AUTOSAR XML (schema 3.2.1)
package /TERootContainer
  composition type Power_Window
    8 x require port:
      PW_cls_unlock: required-interface=cls_unlock
      PW_cls_lock: required-interface=cls_lock
      PW_fp_off: required-interface=fp_off
      PW_pw_pos_dn: required-interface=pw_pos_dn
      PW_fp_on: required-interface=fp_on
      PW_pw_pos_up: required-interface=pw_pos_up
      PW_pw_but_up: required-interface=pw_but_up
      PW_pw_but_dn: required-interface=pw_but_dn
    5 x provide port:
      PW_pw_auto_mv_stop: provided-interface=pw_auto_mv_stop
      PW_pw_auto_mv_up: provided-interface=pw_auto_mv_up
      PW_pw_auto_mv_dn: provided-interface=pw_auto_mv_dn
      PW_pw_mv_dn: provided-interface=pw_mv_dn
      PW_pw_mv_up: provided-interface=pw_mv_up
    component ManPW: type=ManPW
    component AutoPW: type=AutoPW_1
    delegate AutoPW.pw_auto_mv_stop <-> outer port PW_pw_auto_mv_stop
    delegate AutoPW.pw_auto_mv_up <-> outer port PW_pw_auto_mv_up
    delegate AutoPW.pw_auto_mv_dn <-> outer port PW_pw_auto_mv_dn
    delegate ManPW.pw_mv_dn <-> outer port PW_pw_mv_dn
    delegate ManPW.pw_mv_up <-> outer port PW_pw_mv_up
    delegate AutoPW.AUtoPW_cls_unlock <-> outer port PW_cls_unlock
    delegate AutoPW.AutoPW_cls_lock <-> outer port PW_cls_lock
    delegate AutoPW.AutoPW_fp_off <-> outer port PW_fp_off
    delegate AutoPW.AutoPW_fp_on <-> outer port PW_fp_on
    delegate AutoPW.AutoPW_pw_but_dn <-> outer port PW_pw_pos_dn
    delegate AutoPW.AutpPW_pw_but_up <-> outer port PW_pw_pos_up
    delegate AutoPW.AutoPW_pw_pos_up <-> outer port PW_pw_but_up
    delegate AutoPW.AutoPW_pw_pos_dn <-> outer port PW_pw_but_dn
    delegate ManPW.ManPW_cls_unlock <-> outer port PW_cls_unlock
    delegate ManPW.ManPW_cls_lock <-> outer port PW_cls_lock
    delegate ManPW.ManPW_fp_off <-> outer port PW_fp_off
    delegate ManPW.ManPW_fp_on <-> outer port PW_fp_on
    delegate ManPW.ManPW_pw_but_dn <-> outer port PW_pw_pos_dn
    delegate ManPW.ManPW_pw_but_up <-> outer port PW_pw_pos_up
    delegate ManPW.ManPW_pw_pos_up <-> outer port PW_pw_but_up
    delegate ManPW.ManPW_pw_pos_dn <-> outer port PW_pw_but_dn
  composition type ManPW
    8 x require port:
      ManPW_cls_unlock: required-interface=cls_unlock
      ManPW_cls_lock: required-interface=cls_lock
      ManPW_fp_off: required-interface=fp_off
      ManPW_fp_on: required-interface=fp_on
      ManPW_pw_pos_dn: required-interface=pw_but_dn
      ManPW_pw_pos_up: required-interface=pw_but_up
      ManPW_pw_but_up: required-interface=pw_pos_up
      ManPW_pw_but_dn: required-interface=pw_pos_dn
    provide port pw_mv_dn: provided-interface=pw_mv_dn
    provide port pw_mv_up: provided-interface=pw_mv_up
  composition type System_Software_Architecture  # System Software Architecture
    51 x component:
      Power_Window: type=Power_Window
      LED_AlarmSystemInteriorMonit: type=LED_AlarmSystemInteriorMonit_1  # LED_AlarmSystemInteriorMonitoring
      LED_AlarmSystemAlarm: type=LED_AlarmSystemAlarm_1
      LED_AlarmSystemAlarmDetected: type=LED_AlarmSystemAlarmDetected_1
      LED_AlaramSystemActive: type=LED_AlaramSystemActive_1
      LED_CentralLockingSystem: type=LED_CentralLockingSystem_1
      LED_FingerProtection: type=LED_FingerProtection_1
      LED_ExteriorMirrorHeating: type=LED_ExteriorMirrorHeating_1
      LED_ExteriorMirrorBottom: type=LED_ExteriorMirrorBottom_1
      LED_ExteriorMirrorRight: type=LED_ExteriorMirrorRight_1
      LED_ExteriorMirrorLeft: type=LED_ExteriorMirrorLeft_1
      LED_ExteriorMirrorTop: type=LED_ExteriorMirrorTop_1
      LED_AutomaticPowerWindow: type=LED_AutomaticPowerWindow_1
      LED_ManualPowerWindow: type=LED_ManualPowerWindow_1
      HumanMachineInterface: type=HumanMachineInterface_1
      CentralLockingSystem: type=CentralLockingSystem_1
      RemoteControlKeyController: type=RemoteControlKeyController_1
      AlarmSystem: type=AlarmSystem_1
      FingerProtection: type=FingerProtection_1
      ExteriorMirror: type=ExteriorMirror_1
      PW_Remote_Control: type=PW_Remote_Control
      Remote_Cotroll_Key: type=Remote_Cotroll_Key
      PW_Button_DN: type=PW_Button_DN
      PW_Button_UP: type=PW_Button_UP
      Alarm_System_Control: type=Alarm_System_Control
      EM_Button: type=EM_Button
      Alarm_Sensor: type=Alarm_Sensor
      LED_ASIM: type=LED_ASIM
      LED_ASAC: type=LED_ASAC
      LED_ASA: type=LED_ASA
      LED_ASAD: type=LED_ASAD
      LED_PW_CLS_UP: type=LED_PW_CLS_UP
      LED_PW_down: type=LED_PW_down
      LED_PW_UP: type=LED_PW_UP
      LED_Heating: type=LED_Heating
      LED_EM_Left: type=LED_EM_Left
      LED_EM_Right: type=LED_EM_Right
      LED_EM_Top: type=LED_EM_Top
      LED_EM_Bottom: type=LED_EM_Bottom
      EM_Motor: type=EM_Motor
      LED_FP: type=LED_FP
      Heating_timer: type=Heating_timer
      Thermometer: type=Thermometer
      EM_Pos_Sensor: type=EM_Pos_Sensor
      Finger_Sensor_SWA: type=Finger_Sensor_SWA
      PW_pos_Sensor: type=PW_pos_Sensor
      Car_locking_system: type=Car_locking_system
      door_sensor: type=door_sensor
      driving_sensor: type=driving_sensor
      Key_Pos_Sensor: type=Key_Pos_Sensor
      CLS_LED: type=CLS_LED
    connect .PW_pw_mv_dn -> LED_ManualPowerWindow.pw_mv_dn
    connect .PW_pw_mv_up -> LED_ManualPowerWindow.pw_mv_up
    connect .PW_pw_auto_mv_dn -> LED_AutomaticPowerWindow.pw_auto_mv_dn  # PW_to_LED_AutoPW_pw_auto_mv_dn
    connect .PW_pw_auto_mv_up -> LED_AutomaticPowerWindow.pw_auto_mv_up  # PW_to_LED_AutpPW_pw_auto_mv_up
    connect .PW_pw_auto_mv_stop -> LED_AutomaticPowerWindow.pw_auto_mv_stop  # PW_to_LED_AutpPW_pw_auto_mv_stop
    connect PW_pos_Sensor.pw_pos_dn -> .PW_pw_pos_dn
    connect PW_pos_Sensor.pw_pos_up -> .PW_pw_pos_up
    connect HumanMachineInterface.pw_but_up -> .PW_pw_but_up
    connect FingerProtection.fp_off -> .PW_fp_off
    connect FingerProtection.fp_on -> .PW_fp_on
    connect CentralLockingSystem.cls_unlock -> .PW_cls_unlock
    connect CentralLockingSystem.cls_lock -> .PW_cls_lock
    connect RemoteControlKeyController.pw_but_dn -> .PW_pw_but_dn
    connect RemoteControlKeyController.pw_but_up -> .PW_pw_but_up
    connect HumanMachineInterface.pw_but_dn -> .PW_pw_but_dn
    connect Key_Pos_Sensor.key_pos_unlock -> AlarmSystem.key_pos_unlock  # Key_Pos_Sensor_to_AS_key_pos_unlock
    connect Key_Pos_Sensor.key_pos_lock -> AlarmSystem.key_pos_lock  # Key_pos_Sensor_to_AS_key_pos_lock
    connect RemoteControlKeyController.rck_unlock -> AlarmSystem.rck_unlock
    connect RemoteControlKeyController.rck_lock -> AlarmSystem.rck_lock
    connect RemoteControlKeyController.rck_unlock -> CentralLockingSystem.rck_unlock
    connect RemoteControlKeyController.rck_lock -> CentralLockingSystem.rck_lock
    connect door_sensor.door_open -> CentralLockingSystem.door_open
    connect door_sensor.door_open -> RemoteControlKeyController.door_open  # Door_Sensor_to_RCKC_door_open
    connect LED_AlarmSystemInteriorMonit.led_as_im_alarm_off -> LED_ASIM.led_off
    connect LED_AlarmSystemInteriorMonit.led_as_im_alarm_on -> LED_ASIM.led_on
    connect LED_AlaramSystemActive.led_as_active_off -> LED_ASAC.led_off
    connect LED_AlaramSystemActive.led_as_active_on -> LED_ASAC.led_on
    connect LED_AlarmSystemAlarm.led_as_alarm_off -> LED_ASA.led_off
    connect LED_AlarmSystemAlarm.led_as_alarm_on -> LED_ASA.led_on
    connect LED_AlarmSystemAlarmDetected.led_as_alarm_detected_off -> LED_ASAD.led_off
    connect LED_AlarmSystemAlarmDetected.led_as_alarm_detected_on -> LED_ASAD.led_on
    connect LED_AutomaticPowerWindow.led_pw_dn_off -> LED_PW_down.led_off  # LED_AUTOPW_to_LED_PW_down_off
    connect LED_AutomaticPowerWindow.led_pw_dn_on -> LED_PW_down.led_on
    connect LED_ManualPowerWindow.led_pw_dn_on -> LED_PW_down.led_on
    connect LED_AutomaticPowerWindow.led_pw_cls_up_on -> LED_PW_CLS_UP.led_on  # LED_AUTOPW_to_LED_PW_CLS_UP_on
    connect LED_AutomaticPowerWindow.led_pw_cls_up_off -> LED_PW_CLS_UP.led_off  # LED_AUTOPW_to_LED_PW_CLS_UP_off
    connect LED_ManualPowerWindow.led_pw_dn_off -> LED_PW_down.led_off
    connect LED_ManualPowerWindow.led_pw_up_off -> LED_PW_UP.led_off
    connect LED_ManualPowerWindow.led_pw_up_on -> LED_PW_UP.led_on
    connect LED_AutomaticPowerWindow.led_pw_up_off -> LED_PW_UP.led_off
    connect LED_AutomaticPowerWindow.led_pw_up_on -> LED_PW_UP.led_on
    connect LED_ExteriorMirrorHeating.led_em_heating_off -> LED_Heating.led_off  # LED_EM_Heating_to_LED_Heating_off
    connect LED_ExteriorMirrorHeating.led_em_heating_on -> LED_Heating.led_on  # LED_EM_Heating_to_LED_Heating_on
    connect LED_ExteriorMirrorLeft.led_em_left_off -> LED_EM_Left.led_off  # LED_EM_Left_to_LED_EM_Left_off
    connect LED_ExteriorMirrorLeft.led_em_left_on -> LED_EM_Left.led_on  # LED_EM_Left_to_LED_EM_Left_on
    connect LED_ExteriorMirrorRight.led_em_right_off -> LED_EM_Right.led_off  # LED_EM_Right_to_LED_EM_Right_off
    connect LED_ExteriorMirrorRight.led_em_right_on -> LED_EM_Right.led_on  # LED_EM_Right_to_LED_EM_Right_on
    connect LED_ExteriorMirrorTop.led_em_top_off -> LED_EM_Top.led_off
    connect LED_ExteriorMirrorTop.led_em_top_on -> LED_EM_Top.led_on
    connect LED_ExteriorMirrorBottom.led_em_bottom_off -> LED_EM_Bottom.led_off  # LED_EM_Bottom_to_LED_EM_Bottom_off
    connect LED_ExteriorMirrorBottom.led_em_bottom_on -> LED_EM_Bottom.led_on  # LED_EM_Bottom_to_LED_EM_Bottom_on
    connect LED_FingerProtection.led_fp_off -> LED_FP.led_fp_off  # LED_Fingerprotection_to_LED_FP_off
    connect LED_FingerProtection.led_fp_on -> LED_FP.led_fp_on  # LED_Fingerprotection_to_LED_FP_on
    connect Finger_Sensor_SWA.finger_detected -> FingerProtection.finger_detected  # Finger_Snesor_to_FP_finger_detected
    connect ExteriorMirror.em_mv_down -> EM_Motor.em_mv_down
    connect ExteriorMirror.em_mv_up -> EM_Motor.em_mv_up
    connect ExteriorMirror.em_mv_right -> EM_Motor.em_mv_right
    connect ExteriorMirror.em_mv_left -> EM_Motor.em_mv_left
    connect Heating_timer.heating_time_elapsed -> ExteriorMirror.time_heating_elapsed  # Heating_Timer_to_EM_heating_time_elapsed
    connect Thermometer.em_too_cold -> ExteriorMirror.em_too_cold
    connect EM_Pos_Sensor.em_pos_top -> ExteriorMirror.em_pos_top
    connect EM_Pos_Sensor.em_pos_bottom -> ExteriorMirror.em_pos_bottom  # EM_Pos_Sensor_to_EM_pos_bottom
    connect EM_Pos_Sensor.em_pos_right -> ExteriorMirror.em_pos_right  # EM_Pos_Sensor_to_EM_pos_right
    connect EM_Pos_Sensor.em_pos_left -> ExteriorMirror.em_pos_left
    connect Alarm_Sensor.im_alarm_detected -> AlarmSystem.im_alarm_detected  # Alarm_Sensor_to_Alarm_System_im_alarm_detected
    connect Alarm_Sensor.alarm_detected -> AlarmSystem.as_alarm_detected  # Alarm_Sensor_to_Alarm_System_alarm_detected
    connect Alarm_Sensor.alarm_time_elapsed -> AlarmSystem.time_alarm_elapsed  # Alarm_Sensor_to_Alarm_System_time_alarm_elapsed
    connect Key_Pos_Sensor.key_pos_unlock -> CentralLockingSystem.key_pos_unlock
    connect Key_Pos_Sensor.key_pos_lock -> CentralLockingSystem.key_pos_lock
    connect driving_sensor.car_drives -> CentralLockingSystem.car_drives  # Drinving_Sensor_to_CLS_car_drives
    connect PW_Remote_Control.pw_but_down -> RemoteControlKeyController.pw_rm_dn
    connect PW_Remote_Control.pw_but_up -> RemoteControlKeyController.pw_rm_up
    connect Remote_Cotroll_Key.rck_timer -> RemoteControlKeyController.time_rck_sf_elapsed
    connect Remote_Cotroll_Key.rck_but_unlock -> RemoteControlKeyController.rck_but_unlock
    connect Remote_Cotroll_Key.rck_but_lock -> RemoteControlKeyController.rck_but_lock
    connect PW_Button_DN.pw_but_released -> HumanMachineInterface.release_pw_but_dn
    connect PW_Button_DN.pw_but_pressed -> HumanMachineInterface.pw_but_mv_dn
    connect PW_Button_UP.pw_but_released -> HumanMachineInterface.release_pw_but_up
    connect PW_Button_UP.pw_but_pressed -> HumanMachineInterface.pw_but_mv_up
    connect Alarm_System_Control.confirm_alarm -> HumanMachineInterface.confirm_alarm
    connect Alarm_System_Control.deactivate_as -> HumanMachineInterface.deactivate_as
    connect Alarm_System_Control.activate_as -> HumanMachineInterface.activate_as
    connect EM_Button.em_but_mv_dn -> HumanMachineInterface.em_but_mv_dn
    connect EM_Button.em_but_mv_up -> HumanMachineInterface.em_but_mv_up
    connect EM_Button.em_but_mv_right -> HumanMachineInterface.em_but_mv_right  # EM_Button_to_HMI_but_mv_right
    connect EM_Button.em_but_mv_left -> HumanMachineInterface.em_but_mv_left
    connect CentralLockingSystem.car_unlock -> Car_locking_system.car_unlock
    connect CentralLockingSystem.car_lock -> Car_locking_system.car_lock
    connect LED_CentralLockingSystem.led_cls_off -> CLS_LED.led_cls_off
    connect LED_CentralLockingSystem.led_cls_on -> CLS_LED.led_cls_on
    connect ExteriorMirror.heating_on -> LED_ExteriorMirrorHeating.heating_on
    connect ExteriorMirror.heating_off -> LED_ExteriorMirrorHeating.heating_off
    connect ExteriorMirror.em_pos_hor_left -> LED_ExteriorMirrorLeft.em_pos_hor_left  # EM_to_LED_EML_em_pos_hor_left
    connect ExteriorMirror.em_pos_hor_pend -> LED_ExteriorMirrorLeft.em_pos_hor_pend  # EM_to_LED_EML_em_pos_hor_pend
    connect ExteriorMirror.em_pos_hor_pend -> LED_ExteriorMirrorRight.em_pos_hor_pend  # EM_to_LED_EMR_em_pos_hor_pend
    connect ExteriorMirror.em_pos_hor_right -> LED_ExteriorMirrorRight.em_pos_hor_right  # EM_to_LED_EMR_em_pos_hor_right
    connect ExteriorMirror.em_pos_vert_top -> LED_ExteriorMirrorTop.em_pos_vert_top  # EM_to_LED_EMT_em_pos_vert_top
    connect ExteriorMirror.em_pos_vert_pend -> LED_ExteriorMirrorTop.em_pos_vert_pend  # EM_to_LED_EMT_em_pos_vert_pend
    connect ExteriorMirror.em_pos_vert_pend -> LED_ExteriorMirrorBottom.em_pos_vert_pend  # EM_to_LED_EMB_em_pos_vert_pend
    connect ExteriorMirror.em_pos_vert_bottom -> LED_ExteriorMirrorBottom.em_pos_vert_bottom  # EM_to_LED_EMB_em_pos_vert_bottom
    connect HumanMachineInterface.release_pw_but -> LED_ManualPowerWindow.release_pw_but  # HMI_to_LED_ManPW_release_pw_but
    connect AlarmSystem.as_im_alarm_off -> LED_AlarmSystemInteriorMonit.as_im_alarm_off  # AS_to_LED_ASIM_as_im_alarm_off
    connect AlarmSystem.as_im_alarm_on -> LED_AlarmSystemInteriorMonit.as_im_alarm_on  # AS_to_LED_ASIM_as_im_alarm_on
    connect AlarmSystem.as_active_off -> LED_AlaramSystemActive.as_active_off
    connect AlarmSystem.as_active_on -> LED_AlaramSystemActive.as_active_on
    connect CentralLockingSystem.cls_lock -> LED_AutomaticPowerWindow.cls_lock
    connect CentralLockingSystem.cls_unlock -> LED_AutomaticPowerWindow.cls_unlock
    connect AlarmSystem.as_alarm_off -> LED_AlarmSystemAlarm.as_alarm_off
    connect AlarmSystem.as_alarm_on -> LED_AlarmSystemAlarm.as_alarm_on
    connect AlarmSystem.as_alarm_was_detected -> LED_AlarmSystemAlarmDetected.as_alarm_was_detected  # AS_to_LED_ASAD_as_alarm_was_detected
    connect HumanMachineInterface.as_alarm_was_confirmed -> LED_AlarmSystemAlarmDetected.as_alarm_was_confirmed  # HMI_LED_ASAD_alram_was_confirmed
    connect FingerProtection.fp_off -> LED_FingerProtection.fp_off
    connect FingerProtection.fp_on -> LED_FingerProtection.fp_on
    connect HumanMachineInterface.as_activated -> AlarmSystem.as_activated
    connect HumanMachineInterface.as_deactivated -> AlarmSystem.as_deactivated
    connect CentralLockingSystem.cls_lock -> LED_CentralLockingSystem.cls_lock
    connect CentralLockingSystem.cls_unlock -> LED_CentralLockingSystem.cls_unlock
    connect HumanMachineInterface.pw_but_dn -> FingerProtection.pw_but_dn
    connect HumanMachineInterface.em_but_left -> ExteriorMirror.em_but_left
    connect HumanMachineInterface.em_but_up -> ExteriorMirror.em_but_up
    connect HumanMachineInterface.em_but_dn -> ExteriorMirror.em_but_down
    connect HumanMachineInterface.em_but_right -> ExteriorMirror.em_but_right
package /SystemInformation
  system System_System_Software_Architecture:
    fibex-element=[ECU2_HMI, ECU1_Doorsystem, CLS_ECU4, Alarm_System_ECU3, LED_PW_Up, LED_PW_DN, LED_PW_CLS, LED_FP, LED_EMT, LED_EMR, LED_EML, LED_EMB, LED_EM_Heating, LED_CLS, LED_ASIM, LED_ASAL, LED_ASAD, LED_ASAC, EM_Motor, Car_Locking_System, Thermoeter, Remote_Control_Key, RCK_PW_Buttons, PW_Position_Sensor, PW_But_UP, PW_But_DN, Key_Pos_Sensor, Heating_Timer, Finger_Sensor_HW, EM_Pos_Sensor, EM_Button, Driving_Snesor, Door_Sensor, Alarm_System_Control, Alarm_Sensor]
    pnc-vector-length=0
    pnc-vector-offset=0
    mapping Mapping
      sw-impl-mappings:
        20 x swc to impl mapping:
          swcMapping_FingerProtection: component-implementation=Impl_FingerProtection, component=System_Software_Architecture.FingerProtection
          swcMapping_LED_AlarmSystemAl_1: component-implementation=Impl_LED_AlarmSystemAlarmDet, component=System_Software_Architecture.LED_AlarmSystemAlarmDetected
          swcMapping_LED_ExteriorMirro_4: component-implementation=Impl_LED_ExteriorMirrorTop, component=System_Software_Architecture.LED_ExteriorMirrorTop
          swcMapping_AutoPW: component-implementation=Impl_AutoPW, component=System_Software_Architecture.Power_Window.AutoPW
          swcMapping_LED_ManualPowerWi: component-implementation=Impl_LED_ManualPowerWindow, component=System_Software_Architecture.LED_ManualPowerWindow
          swcMapping_LED_ExteriorMirro_2: component-implementation=Impl_LED_ExteriorMirrorRight, component=System_Software_Architecture.LED_ExteriorMirrorRight
          swcMapping_ExteriorMirror: component-implementation=Impl_ExteriorMirror, component=System_Software_Architecture.ExteriorMirror
          swcMapping_LED_ExteriorMirro_3: component-implementation=Impl_LED_ExteriorMirrorLeft, component=System_Software_Architecture.LED_ExteriorMirrorLeft
          swcMapping_LED_AlaramSystemA: component-implementation=Impl_LED_AlaramSystemActive, component=System_Software_Architecture.LED_AlaramSystemActive
          swcMapping_RemoteControlKeyC: component-implementation=Impl_RemoteControlKeyControl, component=System_Software_Architecture.RemoteControlKeyController
          swcMapping_LED_ExteriorMirro_1: component-implementation=Impl_LED_ExteriorMirrorBotto, component=System_Software_Architecture.LED_ExteriorMirrorBottom
          swcMapping_LED_AlarmSystemAl: component-implementation=Impl_LED_AlarmSystemAlarm, component=System_Software_Architecture.LED_AlarmSystemAlarm
          swcMapping_LED_FingerProtect: component-implementation=Impl_LED_FingerProtection, component=System_Software_Architecture.LED_FingerProtection
          swcMapping_LED_AlarmSystemIn: component-implementation=Impl_LED_AlarmSystemInterior, component=System_Software_Architecture.LED_AlarmSystemInteriorMonit
          swcMapping_LED_AutomaticPowe: component-implementation=Impl_LED_AutomaticPowerWindo, component=System_Software_Architecture.LED_AutomaticPowerWindow
          swcMapping_CentralLockingSys: component-implementation=Impl_CentralLockingSystem, component=System_Software_Architecture.CentralLockingSystem
          swcMapping_LED_CentralLockin: component-implementation=Impl_LED_CentralLockingSyste, component=System_Software_Architecture.LED_CentralLockingSystem
          swcMapping_LED_ExteriorMirro: component-implementation=Impl_LED_ExteriorMirrorHeati, component=System_Software_Architecture.LED_ExteriorMirrorHeating
          swcMapping_HumanMachineInter: component-implementation=Impl_HumanMachineInterface, component=System_Software_Architecture.HumanMachineInterface
          swcMapping_AlarmSystem: component-implementation=Impl_AlarmSystem, component=System_Software_Architecture.AlarmSystem
      sw-mappings:
        34 x swc to ecu mapping:
          LED_EMB_FBMapping: component=System_Software_Architecture.LED_EM_Bottom, ecu-instance=LED_EMB
          LED_EMR_FBMapping: component=System_Software_Architecture.LED_EM_Right, ecu-instance=LED_EMR
          LED_EML_FBMapping: component=System_Software_Architecture.LED_EM_Left, ecu-instance=LED_EML
          ECU2_HMI_FBMapping: ecu-instance=ECU2_HMI
            component:
              System_Software_Architecture.LED_ExteriorMirrorBottom
              System_Software_Architecture.LED_ExteriorMirrorRight
              System_Software_Architecture.LED_FingerProtection
              System_Software_Architecture.LED_ExteriorMirrorHeating
              System_Software_Architecture.LED_ExteriorMirrorLeft
              System_Software_Architecture.LED_ManualPowerWindow
              System_Software_Architecture.LED_AutomaticPowerWindow
              System_Software_Architecture.HumanMachineInterface
              System_Software_Architecture.LED_CentralLockingSystem
              System_Software_Architecture.LED_ExteriorMirrorTop
              System_Software_Architecture.LED_AlarmSystemAlarm
              System_Software_Architecture.LED_AlarmSystemInteriorMonit
              System_Software_Architecture.LED_AlaramSystemActive
              System_Software_Architecture.LED_AlarmSystemAlarmDetected
          ECU1_Doorsystem_FBMapping: ecu-instance=ECU1_Doorsystem
            component:
              System_Software_Architecture.ExteriorMirror
              System_Software_Architecture.Power_Window.ManPW
              System_Software_Architecture.FingerProtection
              System_Software_Architecture.Power_Window.AutoPW
          Finger_Sensor_HW_FBMapping: component=System_Software_Architecture.Finger_Sensor_SWA, ecu-instance=Finger_Sensor_HW
          Remote_Control_Key_FBMapping: component=System_Software_Architecture.Remote_Cotroll_Key, ecu-instance=Remote_Control_Key
          Key_Pos_Sensor_FBMapping: component=System_Software_Architecture.Key_Pos_Sensor, ecu-instance=Key_Pos_Sensor
          RCK_PW_Buttons_FBMapping: component=System_Software_Architecture.PW_Remote_Control, ecu-instance=RCK_PW_Buttons
          EM_Motor_FBMapping: component=System_Software_Architecture.EM_Motor, ecu-instance=EM_Motor
          LED_CLS_FBMapping: component=[System_Software_Architecture.CLS_LED, System_Software_Architecture.LED_PW_CLS_UP], ecu-instance=LED_CLS
          CLS_ECU4_FBMapping: ecu-instance=CLS_ECU4
            component:
              System_Software_Architecture.CentralLockingSystem
              System_Software_Architecture.RemoteControlKeyController
          LED_EM_Heating_FBMapping: component=System_Software_Architecture.LED_Heating, ecu-instance=LED_EM_Heating
          PW_Position_Sensor_FBMapping: component=System_Software_Architecture.PW_pos_Sensor, ecu-instance=PW_Position_Sensor
          PW_But_UP_FBMapping: component=System_Software_Architecture.PW_Button_UP, ecu-instance=PW_But_UP
          Car_Locking_System_FBMapping: component=System_Software_Architecture.Car_locking_system, ecu-instance=Car_Locking_System
          LED_ASAL_FBMapping: component=System_Software_Architecture.LED_ASA, ecu-instance=LED_ASAL
          Alarm_System_Control_FBMappi: component=System_Software_Architecture.Alarm_System_Control, ecu-instance=Alarm_System_Control
          EM_Button_FBMapping: component=System_Software_Architecture.EM_Button, ecu-instance=EM_Button
          Alarm_System_ECU3_FBMapping: component=System_Software_Architecture.AlarmSystem, ecu-instance=Alarm_System_ECU3
          LED_EMT_FBMapping: component=System_Software_Architecture.LED_EM_Top, ecu-instance=LED_EMT
          LED_PW_DN_FBMapping: component=System_Software_Architecture.LED_PW_down, ecu-instance=LED_PW_DN
          LED_ASAD_FBMapping: component=System_Software_Architecture.LED_ASAD, ecu-instance=LED_ASAD
          Door_Sensor_FBMapping: component=System_Software_Architecture.door_sensor, ecu-instance=Door_Sensor
          Thermoeter_FBMapping: component=System_Software_Architecture.Thermometer, ecu-instance=Thermoeter
          Alarm_Sensor_FBMapping: component=System_Software_Architecture.Alarm_Sensor, ecu-instance=Alarm_Sensor
          Heating_Timer_FBMapping: component=System_Software_Architecture.Heating_timer, ecu-instance=Heating_Timer
          LED_ASAC_FBMapping: component=System_Software_Architecture.LED_ASAC, ecu-instance=LED_ASAC
          Driving_Snesor_FBMapping: component=System_Software_Architecture.driving_sensor, ecu-instance=Driving_Snesor
          LED_FP_FBMapping: component=System_Software_Architecture.LED_FP, ecu-instance=LED_FP
          PW_But_DN_FBMapping: component=System_Software_Architecture.PW_Button_DN, ecu-instance=PW_But_DN
          LED_ASIM_FBMapping: component=System_Software_Architecture.LED_ASIM, ecu-instance=LED_ASIM
          LED_PW_Up_FBMapping: component=System_Software_Architecture.LED_PW_UP, ecu-instance=LED_PW_Up
          EM_Pos_Sensor_FBMapping: component=System_Software_Architecture.EM_Pos_Sensor, ecu-instance=EM_Pos_Sensor
    software composition System_Software_Architecture: software-composition=System_Software_Architecture
package /Software_Types  # Software Types
package /Software_Types/Interface_Types  # Interface Types
package /Software_Types/Interface_Types/Sender__Receiver_Interfaces  # Sender-/Receiver Interfaces
package /Software_Types/Interface_Types/Sender__Receiver_Interfaces/BCS_Basic/signal_output
  34 x sender receiver interface:
    led_as_im_alarm_off
    led_as_im_alarm_on
    led_as_active_off
    led_as_active_on
    led_as_alarm_off
    led_as_alarm_on
    led_as_alarm_detected_off
    led_as_alarm_detected_on
    led_fp_off
    led_fp_on
    led_cls_off
    led_cls_on
    led_em_heating_off
    led_em_heating_on
    led_em_right_off
    led_em_right_on
    led_em_left_off
    led_em_left_on
    led_em_top_off
    led_em_top_on
    led_em_bottom_off
    led_em_bottom_on
    led_pw_cls_up_off
    led_pw_cls_up_on
    led_pw_dn_off
    led_pw_dn_on
    led_pw_up_off
    led_pw_up_on
    car_unlock
    car_lock
    em_mv_up
    em_mv_right
    em_mv_left
    em_mv_down
package /Software_Types/Interface_Types/Sender__Receiver_Interfaces/BCS_Basic/signal_internal
  36 x sender receiver interface:
    fp_on
    fp_off
    pw_mv_up
    pw_mv_dn
    pw_auto_mv_up
    pw_auto_mv_stop
    pw_auto_mv_dn
    as_alarm_was_confirmed
    release_pw_but
    cls_unlock
    cls_lock
    as_im_alarm_off
    as_im_alarm_on
    as_active_off
    as_active_on
    as_alarm_off
    as_alarm_on
    as_alarm_was_detected
    rck_unlock
    rck_lock
      data rck_lock
    as_deactivated
    as_activated
    heating_off
    heating_on
    em_pos_hor_right
    em_pos_hor_left
    em_pos_vert_top
    em_pos_hor_pend
    em_pos_vert_pend
    em_pos_vert_bottom
    em_but_up
    em_but_left
    em_but_down
    em_but_right
    pw_but_up
    pw_but_dn
package /Software_Types/Interface_Types/Sender__Receiver_Interfaces/BCS_Basic/signal_input
  32 x sender receiver interface:
    finger_detected
    release_pw_but_dn
    release_pw_but_up
    confirm_alarm
    deactivate_as
    activate_as
    em_but_mv_dn
    em_but_mv_up
    em_but_mv_right
    em_but_mv_left
    pw_but_mv_up
    pw_but_mv_dn
    car_drives
    pw_rm_dn
    pw_rm_up
    rck_but_unlock
    rck_but_lock
    time_rck_sf_elapsed
    door_open
    im_alarm_detected
    as_alarm_detected
    time_alarm_elapsed
    key_pos_unlock
    key_pos_lock
    time_heating_elapsed
    em_too_cold
    em_pos_top
    em_pos_bottom
    em_pos_right
    em_pos_left
    pw_pos_up
    pw_pos_dn
package /Software_Types/Block_Types  # Block Types
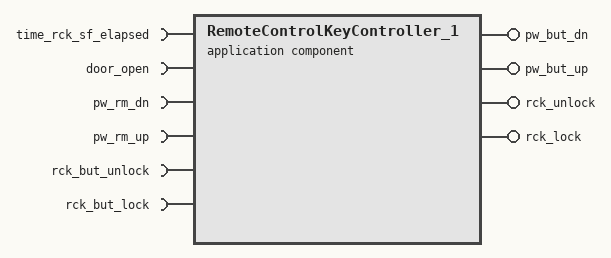
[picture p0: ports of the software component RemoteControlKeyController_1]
  application software component type RemoteControlKeyController_1
    6 x require port:
      time_rck_sf_elapsed: required-interface=time_rck_sf_elapsed
      door_open: required-interface=door_open
      pw_rm_dn: required-interface=pw_rm_dn
      pw_rm_up: required-interface=pw_rm_up
      rck_but_unlock: required-interface=rck_but_unlock
      rck_but_lock: required-interface=rck_but_lock
    4 x provide port:
      pw_but_dn: provided-interface=pw_but_dn
      pw_but_up: provided-interface=pw_but_up
      rck_unlock: provided-interface=rck_unlock
      rck_lock: provided-interface=rck_lock
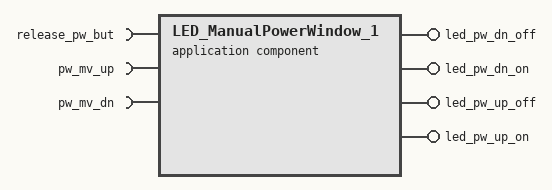
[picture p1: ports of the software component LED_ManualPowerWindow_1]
  application software component type LED_ManualPowerWindow_1
    require port release_pw_but: required-interface=release_pw_but
    require port pw_mv_up: required-interface=pw_mv_up
    require port pw_mv_dn: required-interface=pw_mv_dn
    4 x provide port:
      led_pw_dn_off: provided-interface=led_pw_dn_off
      led_pw_dn_on: provided-interface=led_pw_dn_on
      led_pw_up_off: provided-interface=led_pw_up_off
      led_pw_up_on: provided-interface=led_pw_up_on
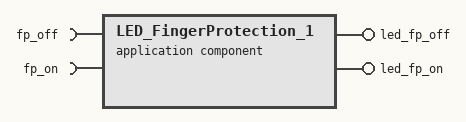
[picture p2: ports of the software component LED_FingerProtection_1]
  application software component type LED_FingerProtection_1
    require port fp_off: required-interface=fp_off
    require port fp_on: required-interface=fp_on
    provide port led_fp_off: provided-interface=led_fp_off
    provide port led_fp_on: provided-interface=led_fp_on
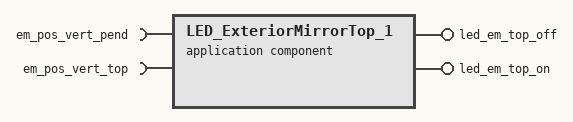
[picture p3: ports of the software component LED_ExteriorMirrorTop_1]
  application software component type LED_ExteriorMirrorTop_1
    require port em_pos_vert_pend: required-interface=em_pos_vert_pend
    require port em_pos_vert_top: required-interface=em_pos_vert_top
    provide port led_em_top_off: provided-interface=led_em_top_off
    provide port led_em_top_on: provided-interface=led_em_top_on
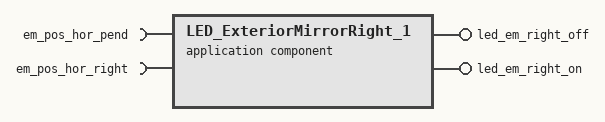
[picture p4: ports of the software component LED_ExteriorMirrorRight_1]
  application software component type LED_ExteriorMirrorRight_1
    require port em_pos_hor_pend: required-interface=em_pos_hor_pend
    require port em_pos_hor_right: required-interface=em_pos_hor_right
    provide port led_em_right_off: provided-interface=led_em_right_off
    provide port led_em_right_on: provided-interface=led_em_right_on
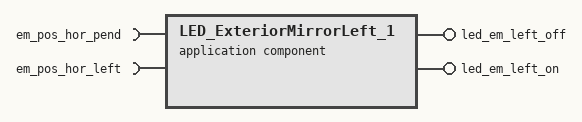
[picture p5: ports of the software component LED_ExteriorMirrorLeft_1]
  application software component type LED_ExteriorMirrorLeft_1
    require port em_pos_hor_pend: required-interface=em_pos_hor_pend
    require port em_pos_hor_left: required-interface=em_pos_hor_left
    provide port led_em_left_off: provided-interface=led_em_left_off
    provide port led_em_left_on: provided-interface=led_em_left_on
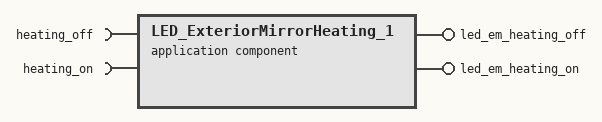
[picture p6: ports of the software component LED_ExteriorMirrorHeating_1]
  application software component type LED_ExteriorMirrorHeating_1
    require port heating_off: required-interface=heating_off
    require port heating_on: required-interface=heating_on
    provide port led_em_heating_off: provided-interface=led_em_heating_off
    provide port led_em_heating_on: provided-interface=led_em_heating_on
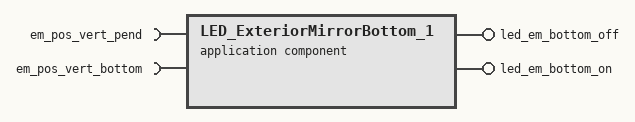
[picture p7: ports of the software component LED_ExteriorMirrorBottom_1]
  application software component type LED_ExteriorMirrorBottom_1
    require port em_pos_vert_pend: required-interface=em_pos_vert_pend
    require port em_pos_vert_bottom: required-interface=em_pos_vert_bottom
    provide port led_em_bottom_off: provided-interface=led_em_bottom_off
    provide port led_em_bottom_on: provided-interface=led_em_bottom_on
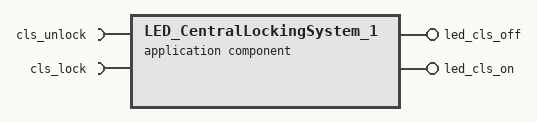
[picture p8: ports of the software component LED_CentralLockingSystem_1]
  application software component type LED_CentralLockingSystem_1
    require port cls_unlock: required-interface=cls_unlock
    require port cls_lock: required-interface=cls_lock
    provide port led_cls_off: provided-interface=led_cls_off
    provide port led_cls_on: provided-interface=led_cls_on
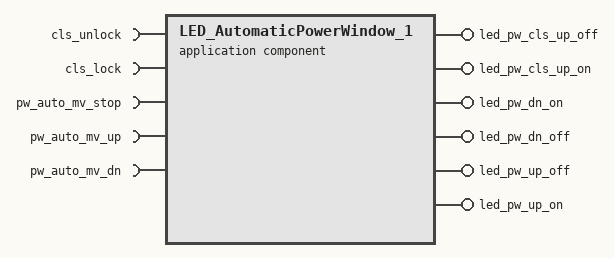
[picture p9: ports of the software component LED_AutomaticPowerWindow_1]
  application software component type LED_AutomaticPowerWindow_1
    5 x require port:
      cls_unlock: required-interface=cls_unlock
      cls_lock: required-interface=cls_lock
      pw_auto_mv_stop: required-interface=pw_auto_mv_stop
      pw_auto_mv_up: required-interface=pw_auto_mv_up
      pw_auto_mv_dn: required-interface=pw_auto_mv_dn
    6 x provide port:
      led_pw_cls_up_off: provided-interface=led_pw_cls_up_off
      led_pw_cls_up_on: provided-interface=led_pw_cls_up_on
      led_pw_dn_on: provided-interface=led_pw_dn_on
      led_pw_dn_off: provided-interface=led_pw_dn_off
      led_pw_up_off: provided-interface=led_pw_up_off
      led_pw_up_on: provided-interface=led_pw_up_on
  application software component type LED_AlarmSystemInteriorMonit_1  # LED_AlarmSystemInteriorMonitoring
    require port as_im_alarm_off: required-interface=as_im_alarm_off
    require port as_im_alarm_on: required-interface=as_im_alarm_on
    provide port led_as_im_alarm_off: provided-interface=led_as_im_alarm_off
    provide port led_as_im_alarm_on: provided-interface=led_as_im_alarm_on
  application software component type LED_AlarmSystemAlarmDetected_1
    require port as_alarm_was_confirmed: required-interface=as_alarm_was_confirmed
    require port as_alarm_was_detected: required-interface=as_alarm_was_detected
    provide port led_as_alarm_detected_off: provided-interface=led_as_alarm_detected_off
    provide port led_as_alarm_detected_on: provided-interface=led_as_alarm_detected_on
  application software component type LED_AlarmSystemAlarm_1
    require port as_alarm_off: required-interface=as_alarm_off
    require port as_alarm_on: required-interface=as_alarm_on
    provide port led_as_alarm_off: provided-interface=led_as_alarm_off
    provide port led_as_alarm_on: provided-interface=led_as_alarm_on
  application software component type LED_AlaramSystemActive_1
    require port as_active_off: required-interface=as_active_off
    require port as_active_on: required-interface=as_active_on
    provide port led_as_active_off: provided-interface=led_as_active_off
    provide port led_as_active_on: provided-interface=led_as_active_on
  application software component type HumanMachineInterface_1
    11 x require port:
      release_pw_but_up: required-interface=release_pw_but_up
      release_pw_but_dn: required-interface=release_pw_but_dn
      confirm_alarm: required-interface=confirm_alarm
      deactivate_as: required-interface=deactivate_as
      activate_as: required-interface=activate_as
      em_but_mv_dn: required-interface=em_but_mv_dn
      em_but_mv_up: required-interface=em_but_mv_up
      em_but_mv_right: required-interface=em_but_mv_right
      em_but_mv_left: required-interface=em_but_mv_left
      pw_but_mv_up: required-interface=pw_but_mv_up
      pw_but_mv_dn: required-interface=pw_but_mv_dn
    10 x provide port:
      release_pw_but: provided-interface=release_pw_but
      as_alarm_was_confirmed: provided-interface=as_alarm_was_confirmed
      as_deactivated: provided-interface=as_deactivated
      as_activated: provided-interface=as_activated
      em_but_right: provided-interface=em_but_right
      em_but_left: provided-interface=em_but_left
      em_but_up: provided-interface=em_but_up
      em_but_dn: provided-interface=em_but_down
      pw_but_dn: provided-interface=pw_but_dn
      pw_but_up: provided-interface=pw_but_up
  application software component type FingerProtection_1
    require port pw_but_dn: required-interface=pw_but_dn
    require port finger_detected: required-interface=finger_detected
    provide port fp_off: provided-interface=fp_off
    provide port fp_on: provided-interface=fp_on
  application software component type ExteriorMirror_1
    10 x require port:
      time_heating_elapsed: required-interface=time_heating_elapsed
      em_too_cold: required-interface=em_too_cold
      em_pos_top: required-interface=em_pos_top
      em_pos_bottom: required-interface=em_pos_bottom
      em_pos_right: required-interface=em_pos_right
      em_pos_left: required-interface=em_pos_left
      em_but_left: required-interface=em_but_left
      em_but_up: required-interface=em_but_up
      em_but_down: required-interface=em_but_down
      em_but_right: required-interface=em_but_right
    12 x provide port:
      em_pos_hor_left: provided-interface=em_pos_hor_left
      em_pos_hor_right: provided-interface=em_pos_hor_right
      em_pos_hor_pend: provided-interface=em_pos_hor_pend
      em_pos_vert_top: provided-interface=em_pos_vert_top
      em_pos_vert_bottom: provided-interface=em_pos_vert_bottom
      em_pos_vert_pend: provided-interface=em_pos_vert_pend
      heating_on: provided-interface=heating_on
      heating_off: provided-interface=heating_off
      em_mv_down: provided-interface=em_mv_down
      em_mv_up: provided-interface=em_mv_up
      em_mv_right: provided-interface=em_mv_right
      em_mv_left: provided-interface=em_mv_left
  application software component type CentralLockingSystem_1
    6 x require port:
      door_open: required-interface=door_open
      car_drives: required-interface=car_drives
      rck_unlock: required-interface=rck_unlock
      rck_lock: required-interface=rck_lock
      key_pos_unlock: required-interface=key_pos_unlock
      key_pos_lock: required-interface=key_pos_lock
    4 x provide port:
      car_unlock: provided-interface=car_unlock
      car_lock: provided-interface=car_lock
      cls_unlock: provided-interface=cls_unlock
      cls_lock: provided-interface=cls_lock
  application software component type AlarmSystem_1
    9 x require port:
      im_alarm_detected: required-interface=im_alarm_detected
      rck_unlock: required-interface=rck_unlock
      rck_lock: required-interface=rck_lock
      as_deactivated: required-interface=as_deactivated
      as_activated: required-interface=as_activated
      time_alarm_elapsed: required-interface=time_alarm_elapsed
      as_alarm_detected: required-interface=as_alarm_detected
      key_pos_unlock: required-interface=key_pos_unlock
      key_pos_lock: required-interface=key_pos_lock
    7 x provide port:
      as_im_alarm_off: provided-interface=as_im_alarm_off
      as_im_alarm_on: provided-interface=as_im_alarm_on
      as_alarm_was_detected: provided-interface=as_alarm_was_detected
      as_alarm_on: provided-interface=as_alarm_on
      as_alarm_off: provided-interface=as_alarm_off
      as_active_off: provided-interface=as_active_off
      as_active_on: provided-interface=as_active_on
  19 x internal behavior:
    LED_AlarmSystemInteriorMonit
    LED_AlarmSystemAlarm
    LED_AlarmSystemAlarmDetected
    LED_AlaramSystemActive
    LED_CentralLockingSystem
    LED_FingerProtection
    LED_ExteriorMirrorHeating
    LED_ExteriorMirrorBottom
    LED_ExteriorMirrorRight
    LED_ExteriorMirrorLeft
    LED_ExteriorMirrorTop
    LED_AutomaticPowerWindow
    LED_ManualPowerWindow
    HumanMachineInterface
    CentralLockingSystem
    RemoteControlKeyController
    AlarmSystem
    FingerProtection
    ExteriorMirror
package /Software_Types/Block_Types/PowerWindow_PW_  # PowerWindow(PW)
  application software component type AutoPW_1
    8 x require port:
      AutoPW_fp_off: required-interface=fp_off
      AutoPW_fp_on: required-interface=fp_on
      AutoPW_pw_pos_dn: required-interface=pw_but_dn
      AutoPW_pw_pos_up: required-interface=pw_but_up
      AutoPW_pw_but_dn: required-interface=pw_pos_dn
      AutpPW_pw_but_up: required-interface=pw_pos_up
      AutoPW_cls_lock: required-interface=cls_lock
      AUtoPW_cls_unlock: required-interface=cls_unlock
    provide port pw_auto_mv_stop: provided-interface=pw_auto_mv_stop
    provide port pw_auto_mv_up: provided-interface=pw_auto_mv_up
    provide port pw_auto_mv_dn: provided-interface=pw_auto_mv_dn
  internal behavior AutoPW
package /Software_Types/Block_Types/Sensor_Types  # Sensor Types
  sensor actuator software component type PW_Remote_Control
    provide port pw_but_down: provided-interface=pw_rm_dn
    provide port pw_but_up: provided-interface=pw_rm_up
  sensor actuator software component type Remote_Cotroll_Key
    provide port rck_timer: provided-interface=time_rck_sf_elapsed
    provide port rck_but_unlock: provided-interface=rck_but_unlock
    provide port rck_but_lock: provided-interface=rck_but_lock
  sensor actuator software component type PW_Button_DN
    provide port pw_but_released: provided-interface=release_pw_but_dn
    provide port pw_but_pressed: provided-interface=pw_but_mv_dn
  sensor actuator software component type PW_Button_UP
    provide port pw_but_released: provided-interface=release_pw_but_up
    provide port pw_but_pressed: provided-interface=pw_but_mv_up
  sensor actuator software component type Alarm_System_Control
    provide port confirm_alarm: provided-interface=confirm_alarm
    provide port deactivate_as: provided-interface=deactivate_as
    provide port activate_as: provided-interface=activate_as
  sensor actuator software component type EM_Button
    4 x provide port:
      em_but_mv_dn: provided-interface=em_but_mv_dn
      em_but_mv_up: provided-interface=em_but_mv_up
      em_but_mv_right: provided-interface=em_but_mv_right
      em_but_mv_left: provided-interface=em_but_mv_left
  sensor actuator software component type Alarm_Sensor
    provide port im_alarm_detected: provided-interface=im_alarm_detected
    provide port alarm_detected: provided-interface=as_alarm_detected
    provide port alarm_time_elapsed: provided-interface=time_alarm_elapsed
  sensor actuator software component type Heating_timer
    provide port heating_time_elapsed: provided-interface=time_heating_elapsed
  sensor actuator software component type Thermometer
    provide port em_too_cold: provided-interface=em_too_cold
  sensor actuator software component type EM_Pos_Sensor
    4 x provide port:
      em_pos_top: provided-interface=em_pos_top
      em_pos_bottom: provided-interface=em_pos_bottom
      em_pos_right: provided-interface=em_pos_right
      em_pos_left: provided-interface=em_pos_left
  sensor actuator software component type Finger_Sensor_SWA
    provide port finger_detected: provided-interface=finger_detected
  sensor actuator software component type PW_pos_Sensor
    provide port pw_pos_dn: provided-interface=pw_pos_dn
    provide port pw_pos_up: provided-interface=pw_pos_up
  sensor actuator software component type door_sensor
    provide port door_open: provided-interface=door_open
  sensor actuator software component type driving_sensor
    provide port car_drives: provided-interface=car_drives
  sensor actuator software component type Key_Pos_Sensor
    provide port key_pos_unlock: provided-interface=key_pos_unlock
    provide port key_pos_lock: provided-interface=key_pos_lock
package /Software_Types/Block_Types/Actuator_Types  # Actuator Types
  sensor actuator software component type LED_ASIM
    require port led_off: required-interface=led_as_im_alarm_off
    require port led_on: required-interface=led_as_im_alarm_on
  sensor actuator software component type LED_ASAC
    require port led_off: required-interface=led_as_active_off
    require port led_on: required-interface=led_as_active_on
  sensor actuator software component type LED_ASA
    require port led_off: required-interface=led_as_alarm_off
    require port led_on: required-interface=led_as_alarm_on
  sensor actuator software component type LED_ASAD
    require port led_off: required-interface=led_as_alarm_detected_off
    require port led_on: required-interface=led_as_alarm_detected_on
  sensor actuator software component type LED_PW_CLS_UP
    require port led_off: required-interface=led_pw_cls_up_off
    require port led_on: required-interface=led_pw_cls_up_on
  sensor actuator software component type LED_PW_down
    require port led_off: required-interface=led_pw_dn_off
    require port led_on: required-interface=led_pw_dn_on
  sensor actuator software component type LED_PW_UP
    require port led_off: required-interface=led_pw_up_off
    require port led_on: required-interface=led_pw_up_on
  sensor actuator software component type LED_Heating
    require port led_off: required-interface=led_em_heating_off
    require port led_on: required-interface=led_em_heating_on
  sensor actuator software component type LED_EM_Left
    require port led_off: required-interface=led_em_left_off
    require port led_on: required-interface=led_em_left_on
  sensor actuator software component type LED_EM_Right
    require port led_off: required-interface=led_em_right_off
    require port led_on: required-interface=led_em_right_on
  sensor actuator software component type LED_EM_Top
    require port led_off: required-interface=led_em_top_off
    require port led_on: required-interface=led_em_top_on
  sensor actuator software component type LED_EM_Bottom
    require port led_off: required-interface=led_em_bottom_off
    require port led_on: required-interface=led_em_bottom_on
  sensor actuator software component type EM_Motor
    4 x require port:
      em_mv_down: required-interface=em_mv_down
      em_mv_up: required-interface=em_mv_up
      em_mv_right: required-interface=em_mv_right
      em_mv_left: required-interface=em_mv_left
  sensor actuator software component type LED_FP
    require port led_fp_off: required-interface=led_fp_off
    require port led_fp_on: required-interface=led_fp_on
  sensor actuator software component type Car_locking_system
    require port car_unlock: required-interface=car_unlock
    require port car_lock: required-interface=car_lock
  sensor actuator software component type CLS_LED
    require port led_cls_off: required-interface=led_cls_off
    require port led_cls_on: required-interface=led_cls_on
package /Data_Types  # Data Types
package /Components/Components/Komponentendiagramm/BCS_Basic
  35 x ecu instance, all with com-configuration-id=0, com-processing-period=0.001, com-processing-period-gw=0.0, com-processing-period-rx=0.0, diagnostic-address=0, pdu-r-configuration-id=0, sleep-mode-supported=false, wake-up-over-bus-supported=false:
    ECU2_HMI
      communication connector HMI_Inputbus_LED: nm-address=0
      communication connector HMI_Bus_Connector: nm-address=0
    ECU1_Doorsystem
      communication connector Doorsystem_Outputbus: nm-address=0
      communication connector Doorsystem_Input_Bus_Connect: nm-address=0  # Doorsystem_Input_Bus_Connector
    CLS_ECU4
      communication connector CLS_ECU_Outputbus: nm-address=0
    Alarm_System_ECU3
      communication connector AlarmSystem_Outputbus_Connec: nm-address=0  # AlarmSystem_Outputbus_Connector
      communication connector AlarmSystem_Inputbus_Connect: nm-address=0  # AlarmSystem_Inputbus_Connector
    LED_PW_Up: category=Actuator
    LED_PW_DN: category=Actuator
    LED_PW_CLS: category=Actuator
    LED_FP: category=Actuator
    LED_EMT: category=Actuator
    LED_EMR: category=Actuator
    LED_EML: category=Actuator
    LED_EMB: category=Actuator
    LED_EM_Heating: category=Actuator
    LED_CLS: category=Actuator
    LED_ASIM: category=Actuator
    LED_ASAL: category=Actuator
    LED_ASAD: category=Actuator
    LED_ASAC: category=Actuator
    EM_Motor: category=Actuator
    Car_Locking_System: category=Actuator
    Thermoeter: category=Sensor
    Remote_Control_Key: category=Sensor
    RCK_PW_Buttons: category=Sensor
    PW_Position_Sensor: category=Sensor
    PW_But_UP: category=Sensor
    PW_But_DN: category=Sensor
    Key_Pos_Sensor: category=Sensor
    Heating_Timer: category=Sensor
    Finger_Sensor_HW: category=Sensor
    EM_Pos_Sensor: category=Sensor
    EM_Button: category=Sensor
    Driving_Snesor: category=Sensor
    Door_Sensor: category=Sensor
    Alarm_System_Control: category=Sensor
    Alarm_Sensor: category=Sensor
package /Implementation
  20 x swc implementation, all with sw-major-version=0, sw-minor-version=0, sw-patch-version=0, vendor-id=0:
    Impl_AlarmSystem: behavior=AlarmSystem
    Impl_LED_AlarmSystemInterior: behavior=LED_AlarmSystemInteriorMonit
    Impl_FingerProtection: behavior=FingerProtection
    Impl_LED_CentralLockingSyste: behavior=LED_CentralLockingSystem
    Impl_LED_ExteriorMirrorBotto: behavior=LED_ExteriorMirrorBottom
    Impl_LED_ExteriorMirrorRight: behavior=LED_ExteriorMirrorRight
    Impl_LED_AutomaticPowerWindo: behavior=LED_AutomaticPowerWindow
    Impl_CentralLockingSystem: behavior=CentralLockingSystem
    Impl_HumanMachineInterface: behavior=HumanMachineInterface
    Impl_LED_AlarmSystemAlarmDet: behavior=LED_AlarmSystemAlarmDetected
    Impl_LED_FingerProtection: behavior=LED_FingerProtection
    Impl_LED_ExteriorMirrorLeft: behavior=LED_ExteriorMirrorLeft
    Impl_LED_AlarmSystemAlarm: behavior=LED_AlarmSystemAlarm
    Impl_LED_ExteriorMirrorHeati: behavior=LED_ExteriorMirrorHeating
    Impl_LED_ManualPowerWindow: behavior=LED_ManualPowerWindow
    Impl_AutoPW: behavior=AutoPW
    Impl_LED_ExteriorMirrorTop: behavior=LED_ExteriorMirrorTop
    Impl_LED_AlaramSystemActive: behavior=LED_AlaramSystemActive
    Impl_ExteriorMirror: behavior=ExteriorMirror
    Impl_RemoteControlKeyControl: behavior=RemoteControlKeyController
